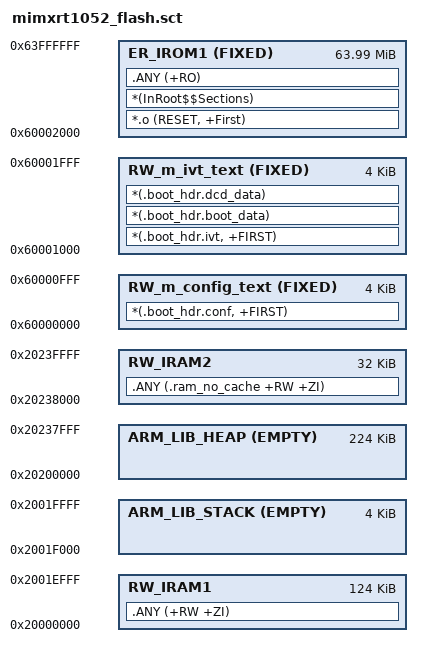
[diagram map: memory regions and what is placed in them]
;*******************************************************************
;* i.MX RT1052 linker scatter file (running code from Hyper Flash) *
;*******************************************************************

LR_IROM1 0x60000000 0x4000000
{
   RW_m_config_text 0x60000000 FIXED 0x1000
   {
      *(.boot_hdr.conf, +FIRST)
   }
   
   RW_m_ivt_text 0x60001000 FIXED 0x1000
   {
      *(.boot_hdr.ivt, +FIRST)
      *(.boot_hdr.boot_data)
      *(.boot_hdr.dcd_data)
   }
   
   ER_IROM1 0x60002000 FIXED 0x03FFE000
   {
      *.o (RESET, +First)
      *(InRoot$$Sections)
      .ANY (+RO)
   }
   
   RW_IRAM1 0x20000000 0x1F000
   {
      .ANY (+RW +ZI)
   }
   
   ARM_LIB_STACK 0x20020000 EMPTY -0x1000
   {
   }
   
   ARM_LIB_HEAP 0x20200000 EMPTY 0x38000
   {
   }
   
   RW_IRAM2 0x20238000 0x8000
   {
      .ANY (.ram_no_cache +RW +ZI)
   }
}
